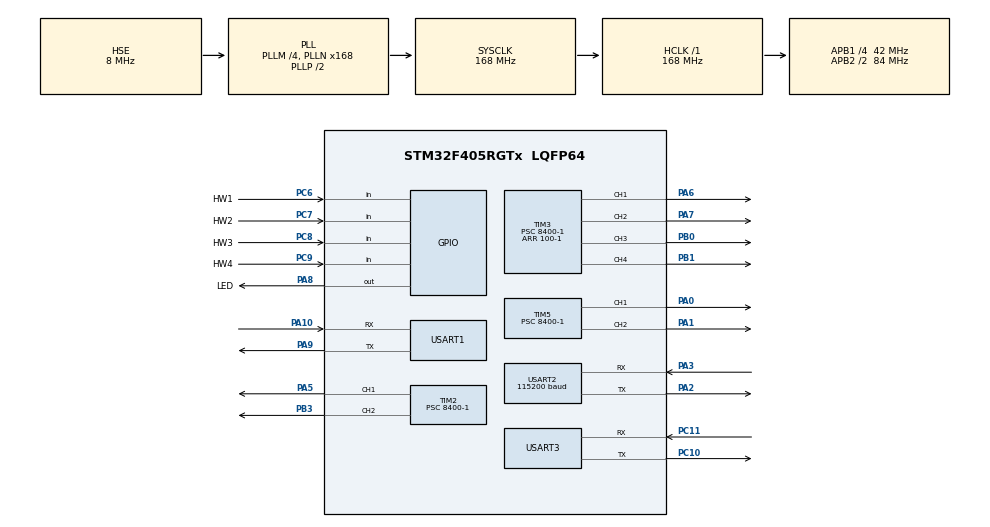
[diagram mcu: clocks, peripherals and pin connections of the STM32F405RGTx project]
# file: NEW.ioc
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Dma.Request0=USART2_RX
Dma.Request1=USART2_TX
Dma.USART2_RX.0.Direction=DMA_PERIPH_TO_MEMORY
Dma.USART2_RX.0.FIFOMode=DMA_FIFOMODE_DISABLE
Dma.USART2_RX.0.Instance=DMA1_Stream5
Dma.USART2_RX.0.MemDataAlignment=DMA_MDATAALIGN_BYTE
Dma.USART2_RX.0.MemInc=DMA_MINC_ENABLE
Dma.USART2_RX.0.Mode=DMA_NORMAL
Dma.USART2_RX.0.PeriphDataAlignment=DMA_PDATAALIGN_BYTE
Dma.USART2_RX.0.PeriphInc=DMA_PINC_DISABLE
Dma.USART2_RX.0.Priority=DMA_PRIORITY_LOW
Dma.USART2_TX.1.Direction=DMA_MEMORY_TO_PERIPH
Dma.USART2_TX.1.FIFOMode=DMA_FIFOMODE_DISABLE
Dma.USART2_TX.1.Instance=DMA1_Stream6
Dma.USART2_TX.1.MemDataAlignment=DMA_MDATAALIGN_BYTE
Dma.USART2_TX.1.MemInc=DMA_MINC_ENABLE
Dma.USART2_TX.1.Mode=DMA_NORMAL
Dma.USART2_TX.1.PeriphDataAlignment=DMA_PDATAALIGN_BYTE
Dma.USART2_TX.1.PeriphInc=DMA_PINC_DISABLE
Dma.USART2_TX.1.Priority=DMA_PRIORITY_LOW
FREERTOS.Tasks01=defaultTask,0,128,StartDefaultTask,Default,NULL,Dynamic,NULL,NULL;Debug_Task,-3,128,Start_Debug_Task,Default,NULL,Dynamic,NULL,NULL;BT_Task,-3,128,BT_Task_Task,Default,NULL,Dynamic,NULL,NULL;Motor_Task,-3,128,Start_Motor_Task,Default,NULL,Dynamic,NULL,NULL
Mcu.Family=STM32F4
Mcu.Name=STM32F405RGTx
Mcu.Package=LQFP64
NVIC.DMA1_Stream5_IRQn=true\:5\:0\:false\:false\:true\:true\:false\:true\:true
NVIC.DMA1_Stream6_IRQn=true\:5\:0\:false\:false\:true\:true\:false\:true\:true
NVIC.PriorityGroup=NVIC_PRIORITYGROUP_4
NVIC.TIM6_DAC_IRQn=true\:15\:0\:false\:false\:true\:false\:false\:true\:true
NVIC.TimeBase=TIM6_DAC_IRQn
NVIC.TimeBaseIP=TIM6
NVIC.USART2_IRQn=true\:5\:0\:false\:false\:false\:true\:true\:true\:true
PA0-WKUP.Signal=S_TIM5_CH1
PA1.Signal=S_TIM5_CH2
PA10.Mode=Asynchronous
PA10.Signal=USART1_RX
PA13.Mode=Serial_Wire
PA13.Signal=SYS_JTMS-SWDIO
PA14.Mode=Serial_Wire
PA14.Signal=SYS_JTCK-SWCLK
PA2.Mode=Asynchronous
PA2.Signal=USART2_TX
PA3.Mode=Asynchronous
PA3.Signal=USART2_RX
PA5.Signal=S_TIM2_CH1_ETR
PA6.Signal=S_TIM3_CH1
PA7.Signal=S_TIM3_CH2
PA8.GPIO_Label=LED
PA8.Signal=GPIO_Output
PA9.Mode=Asynchronous
PA9.Signal=USART1_TX
PB0.Signal=S_TIM3_CH3
PB1.Signal=S_TIM3_CH4
PB3.Signal=S_TIM2_CH2
PC10.Mode=Asynchronous
PC10.Signal=USART3_TX
PC11.Mode=Asynchronous
PC11.Signal=USART3_RX
PC14-OSC32_IN.Mode=LSE-External-Oscillator
PC14-OSC32_IN.Signal=RCC_OSC32_IN
PC15-OSC32_OUT.Mode=LSE-External-Oscillator
PC15-OSC32_OUT.Signal=RCC_OSC32_OUT
PC6.GPIO_Label=HW1
PC6.Signal=GPIO_Input
PC7.GPIO_Label=HW2
PC7.Signal=GPIO_Input
PC8.GPIO_Label=HW3
PC8.Signal=GPIO_Input
PC9.GPIO_Label=HW4
PC9.Signal=GPIO_Input
PH0-OSC_IN.Mode=HSE-External-Oscillator
PH0-OSC_IN.Signal=RCC_OSC_IN
PH1-OSC_OUT.Mode=HSE-External-Oscillator
PH1-OSC_OUT.Signal=RCC_OSC_OUT
ProjectManager.HeapSize=0x200
ProjectManager.StackSize=0x400
ProjectManager.TargetToolchain=MDK-ARM V5.32
RCC.48MHZClocksFreq_Value=84000000
RCC.AHBFreq_Value=168000000
RCC.APB1CLKDivider=RCC_HCLK_DIV4
RCC.APB1Freq_Value=42000000
RCC.APB1TimFreq_Value=84000000
RCC.APB2CLKDivider=RCC_HCLK_DIV2
RCC.APB2Freq_Value=84000000
RCC.APB2TimFreq_Value=168000000
RCC.CortexFreq_Value=168000000
RCC.HCLKFreq_Value=168000000
RCC.HSE_VALUE=8000000
RCC.HSI_VALUE=16000000
RCC.PLLM=4
RCC.PLLN=168
RCC.PLLSourceVirtual=RCC_PLLSOURCE_HSE
RCC.SYSCLKFreq_VALUE=168000000
RCC.SYSCLKSource=RCC_SYSCLKSOURCE_PLLCLK
RCC.VCOOutputFreq_Value=336000000
SH.S_TIM2_CH1_ETR.0=TIM2_CH1,PWM Generation1 CH1
SH.S_TIM2_CH2.0=TIM2_CH2,PWM Generation2 CH2
SH.S_TIM3_CH1.0=TIM3_CH1,PWM Generation1 CH1
SH.S_TIM3_CH2.0=TIM3_CH2,PWM Generation2 CH2
SH.S_TIM3_CH3.0=TIM3_CH3,PWM Generation3 CH3
SH.S_TIM3_CH4.0=TIM3_CH4,PWM Generation4 CH4
SH.S_TIM5_CH1.0=TIM5_CH1,PWM Generation1 CH1
SH.S_TIM5_CH2.0=TIM5_CH2,PWM Generation2 CH2
TIM2.Channel-PWM\ Generation1\ CH1=TIM_CHANNEL_1
TIM2.Channel-PWM\ Generation2\ CH2=TIM_CHANNEL_2
TIM2.Period=100-1
TIM2.Prescaler=8400-1
TIM3.Channel-PWM\ Generation1\ CH1=TIM_CHANNEL_1
TIM3.Channel-PWM\ Generation2\ CH2=TIM_CHANNEL_2
TIM3.Channel-PWM\ Generation3\ CH3=TIM_CHANNEL_3
TIM3.Channel-PWM\ Generation4\ CH4=TIM_CHANNEL_4
TIM3.Period=100-1
TIM3.Prescaler=8400-1
TIM3.Pulse-PWM\ Generation1\ CH1=0
TIM5.Channel-PWM\ Generation1\ CH1=TIM_CHANNEL_1
TIM5.Channel-PWM\ Generation2\ CH2=TIM_CHANNEL_2
TIM5.Period=100-1
TIM5.Prescaler=8400-1
USART1.VirtualMode=VM_ASYNC
USART2.BaudRate=115200
USART2.VirtualMode=VM_ASYNC
USART3.VirtualMode=VM_ASYNC
VP_FREERTOS_VS_CMSIS_V1.Mode=CMSIS_V1
VP_SYS_VS_tim6.Mode=TIM6
VP_TIM2_VS_ClockSourceINT.Mode=Internal
VP_TIM3_VS_ClockSourceINT.Mode=Internal
VP_TIM5_VS_ClockSourceINT.Mode=Internal
board=custom

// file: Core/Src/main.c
/* USER CODE BEGIN Header */
/**
  ******************************************************************************
  * @file           : main.c
  * @brief          : Main program body
  ******************************************************************************
  * @attention
  *
  * Copyright (c) 2022 STMicroelectronics.
  * All rights reserved.
  *
  * This software is licensed under terms that can be found in the LICENSE file
  * in the root directory of this software component.
  * If no LICENSE file comes with this software, it is provided AS-IS.
  *
  ******************************************************************************
  */
/* USER CODE END Header */
#include "main.h"
#include "cmsis_os.h"
#include "dma.h"
#include "tim.h"
#include "usart.h"
#include "gpio.h"

void SystemClock_Config(void);
void MX_FREERTOS_Init(void);

int main(void)
{

  /* MCU Configuration--------------------------------------------------------*/

  /* Reset of all peripherals, Initializes the Flash interface and the Systick. */
  HAL_Init();

  /* Configure the system clock */
  SystemClock_Config();

  /* Initialize all configured peripherals */
  MX_GPIO_Init();
  MX_DMA_Init();
  MX_USART1_UART_Init();
  MX_TIM2_Init();
  MX_USART2_UART_Init();
  MX_TIM3_Init();
  MX_TIM5_Init();
  MX_USART3_UART_Init();

  /* Call init function for freertos objects (in freertos.c) */
  MX_FREERTOS_Init();

  /* Start scheduler */
  osKernelStart();

  /* We should never get here as control is now taken by the scheduler */
  /* Infinite loop */
  while (1)
  {

  }
}

void SystemClock_Config(void)
{
  RCC_OscInitTypeDef RCC_OscInitStruct = {0};
  RCC_ClkInitTypeDef RCC_ClkInitStruct = {0};

  /** Configure the main internal regulator output voltage
  */
  __HAL_RCC_PWR_CLK_ENABLE();
  __HAL_PWR_VOLTAGESCALING_CONFIG(PWR_REGULATOR_VOLTAGE_SCALE1);

  /** Initializes the RCC Oscillators according to the specified parameters
  * in the RCC_OscInitTypeDef structure.
  */
  RCC_OscInitStruct.OscillatorType = RCC_OSCILLATORTYPE_HSE;
  RCC_OscInitStruct.HSEState = RCC_HSE_ON;
  RCC_OscInitStruct.PLL.PLLState = RCC_PLL_ON;
  RCC_OscInitStruct.PLL.PLLSource = RCC_PLLSOURCE_HSE;
  RCC_OscInitStruct.PLL.PLLM = 4;
  RCC_OscInitStruct.PLL.PLLN = 168;
  RCC_OscInitStruct.PLL.PLLP = RCC_PLLP_DIV2;
  RCC_OscInitStruct.PLL.PLLQ = 4;
  if (HAL_RCC_OscConfig(&RCC_OscInitStruct) != HAL_OK)
  {
    Error_Handler();
  }

  /** Initializes the CPU, AHB and APB buses clocks
  */
  RCC_ClkInitStruct.ClockType = RCC_CLOCKTYPE_HCLK|RCC_CLOCKTYPE_SYSCLK
                              |RCC_CLOCKTYPE_PCLK1|RCC_CLOCKTYPE_PCLK2;
  RCC_ClkInitStruct.SYSCLKSource = RCC_SYSCLKSOURCE_PLLCLK;
  RCC_ClkInitStruct.AHBCLKDivider = RCC_SYSCLK_DIV1;
  RCC_ClkInitStruct.APB1CLKDivider = RCC_HCLK_DIV4;
  RCC_ClkInitStruct.APB2CLKDivider = RCC_HCLK_DIV2;

  if (HAL_RCC_ClockConfig(&RCC_ClkInitStruct, FLASH_LATENCY_5) != HAL_OK)
  {
    Error_Handler();
  }
}

void HAL_TIM_PeriodElapsedCallback(TIM_HandleTypeDef *htim)
{
  if (htim->Instance == TIM6) {
    HAL_IncTick();
  }
}

void Error_Handler(void)
{
  __disable_irq();
  while (1)
  {
  }
}

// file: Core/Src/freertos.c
/* USER CODE BEGIN Header */
/**
  ******************************************************************************
  * File Name          : freertos.c
  * Description        : Code for freertos applications
  ******************************************************************************
  * @attention
  *
  * Copyright (c) 2022 STMicroelectronics.
  * All rights reserved.
  *
  * This software is licensed under terms that can be found in the LICENSE file
  * in the root directory of this software component.
  * If no LICENSE file comes with this software, it is provided AS-IS.
  *
  ******************************************************************************
  */
/* USER CODE END Header */

#include "FreeRTOS.h"
#include "task.h"
#include "main.h"
#include "cmsis_os.h"

/* USER CODE BEGIN Includes */
#include "User_Debug.h"
#include "bluetooth.h"
#include "usart.h"
#include "motor.h"
/* USER CODE END Includes */

osThreadId defaultTaskHandle;
osThreadId Debug_TaskHandle;
osThreadId BT_TaskHandle;
osThreadId Motor_TaskHandle;

void StartDefaultTask(void const * argument);
void Start_Debug_Task(void const * argument);
void BT_Task_Task(void const * argument);
void Start_Motor_Task(void const * argument);

void MX_FREERTOS_Init(void); /* (MISRA C 2004 rule 8.1) */

/* GetIdleTaskMemory prototype (linked to static allocation support) */
void vApplicationGetIdleTaskMemory( StaticTask_t **ppxIdleTaskTCBBuffer, StackType_t **ppxIdleTaskStackBuffer, uint32_t *pulIdleTaskStackSize );

/* USER CODE BEGIN GET_IDLE_TASK_MEMORY */
static StaticTask_t xIdleTaskTCBBuffer;
static StackType_t xIdleStack[configMINIMAL_STACK_SIZE];

void vApplicationGetIdleTaskMemory( StaticTask_t **ppxIdleTaskTCBBuffer, StackType_t **ppxIdleTaskStackBuffer, uint32_t *pulIdleTaskStackSize )
{
  *ppxIdleTaskTCBBuffer = &xIdleTaskTCBBuffer;
  *ppxIdleTaskStackBuffer = &xIdleStack[0];
  *pulIdleTaskStackSize = configMINIMAL_STACK_SIZE;
  /* place for user code */
}
/* USER CODE END GET_IDLE_TASK_MEMORY */

void MX_FREERTOS_Init(void) {

  /* Create the thread(s) */
  /* definition and creation of defaultTask */
  osThreadDef(defaultTask, StartDefaultTask, osPriorityNormal, 0, 128);
  defaultTaskHandle = osThreadCreate(osThread(defaultTask), NULL);

  /* definition and creation of Debug_Task */
  osThreadDef(Debug_Task, Start_Debug_Task, osPriorityIdle, 0, 128);
  Debug_TaskHandle = osThreadCreate(osThread(Debug_Task), NULL);

  /* definition and creation of BT_Task */
  osThreadDef(BT_Task, BT_Task_Task, osPriorityIdle, 0, 128);
  BT_TaskHandle = osThreadCreate(osThread(BT_Task), NULL);

  /* definition and creation of Motor_Task */
  osThreadDef(Motor_Task, Start_Motor_Task, osPriorityIdle, 0, 128);
  Motor_TaskHandle = osThreadCreate(osThread(Motor_Task), NULL);

}

void StartDefaultTask(void const * argument)
{
  /* USER CODE BEGIN StartDefaultTask */
  /* Infinite loop */
  for(;;)
  {

		HAL_GPIO_TogglePin(LED_GPIO_Port, LED_Pin);
//		usart_printf("helloworld\r\n");
    osDelay(500);
  }
  /* USER CODE END StartDefaultTask */
}

void Start_Debug_Task(void const * argument)
{
  /* USER CODE BEGIN Start_Debug_Task */
  /* Infinite loop */
  for(;;)
  {
		Debug_Usart();
    osDelay(1);
  }
  /* USER CODE END Start_Debug_Task */
}

void BT_Task_Task(void const * argument)
{
  /* USER CODE BEGIN BT_Task_Task */
	BT_init();
//		uint8_t rx = 0;
  /* Infinite loop */
  for(;;)
  {
//		HAL_UART_Receive(&huart2,&rx,1,HAL_MAX_DELAY);
//		usart_printf("%c\r\n",rx);
		Check_Rx();
    osDelay(10);
  }
  /* USER CODE END BT_Task_Task */
}

void Start_Motor_Task(void const * argument)
{
  /* USER CODE BEGIN Start_Motor_Task */
		motor_init();
  /* Infinite loop */
  for(;;)
  {
		motor();
    osDelay(1);
  }
  /* USER CODE END Start_Motor_Task */
}
